# pwm register map
Vendor: Texas Instruments
Peripheral module from a debugger description file (folder sc4ce93xh6pm).
Registers are 32-bit, read-write, no defined reset value unless marked. A register's access mark holds for its fields unless they carry their own. Offsets are as the file gives them; lines under a group give offsets from that group; [hi:lo] are bit positions; {n}, {i} and the like mark numbered series; 'fields as' and 'values as' point back to an identical list; <NAME> marks a mode.

## PWM0 — PWM register offsets
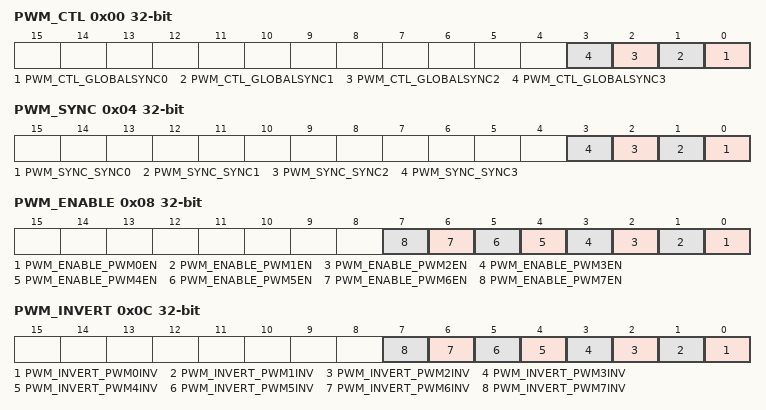
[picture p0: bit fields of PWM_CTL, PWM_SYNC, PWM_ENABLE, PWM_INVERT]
0x00 PWM_CTL — PWM Master Control
  [n] PWM_CTL_GLOBALSYNC{n} (n=0..3) — Update PWM Generator {n}
0x04 PWM_SYNC — PWM Time Base Sync
  [n] PWM_SYNC_SYNC{n} (n=0..3) — Reset Generator {n} Counter
0x08 PWM_ENABLE — PWM Output Enable
  [n] PWM_ENABLE_PWM{n}EN (n=0..7) — MnPWM{n} Output Enable
0x0C PWM_INVERT — PWM Output Inversion
  [n] PWM_INVERT_PWM{n}INV (n=0..7) — Invert MnPWM{n} Signal
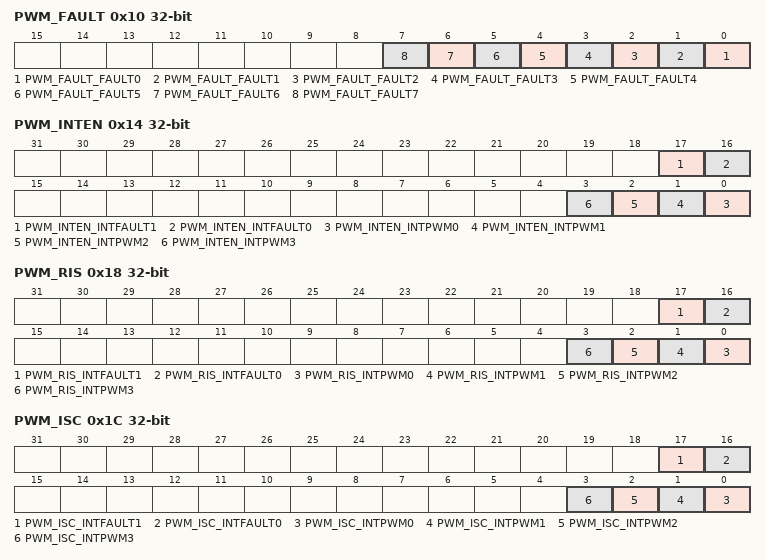
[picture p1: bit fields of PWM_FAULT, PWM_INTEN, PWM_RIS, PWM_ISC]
0x10 PWM_FAULT — PWM Output Fault
  [n] PWM_FAULT_FAULT{n} (n=0..7) — MnPWM{n} Fault
0x14 PWM_INTEN — PWM Interrupt Enable
  [17] PWM_INTEN_INTFAULT1 — Interrupt Fault 1
  [16] PWM_INTEN_INTFAULT0 — Interrupt Fault 0
  [n] PWM_INTEN_INTPWM{n} (n=0..3) — PWM{n} Interrupt Enable
0x18 PWM_RIS ro — PWM Raw Interrupt Status
  [17] PWM_RIS_INTFAULT1 — Interrupt Fault PWM 1
  [16] PWM_RIS_INTFAULT0 — Interrupt Fault PWM 0
  [n] PWM_RIS_INTPWM{n} (n=0..3) — PWM{n} Interrupt Asserted
0x1C PWM_ISC — PWM Interrupt Status and Clear
  [17] PWM_ISC_INTFAULT1 — FAULT1 Interrupt Asserted
  [16] PWM_ISC_INTFAULT0 — FAULT0 Interrupt Asserted
  [n] PWM_ISC_INTPWM{n} (n=0..3) — PWM{n} Interrupt Status
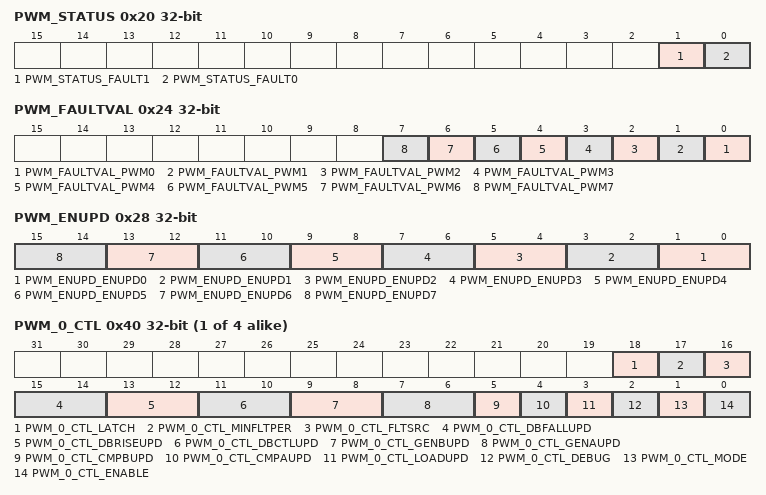
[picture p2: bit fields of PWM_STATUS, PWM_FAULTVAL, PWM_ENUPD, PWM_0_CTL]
0x20 PWM_STATUS ro
  [1] PWM_STATUS_FAULT1 — Generator 1 Fault Status
  [0] PWM_STATUS_FAULT0 — Generator 0 Fault Status
0x24 PWM_FAULTVAL — PWM Fault Condition Value
  [n] PWM_FAULTVAL_PWM{n} (n=0..7) — MnPWM{n} Fault Value
0x28 PWM_ENUPD — PWM Enable Update
  [2n+1:2n] PWM_ENUPD_ENUPD{n} (n=0..7) — MnPWM{n} Enable Update Mode
    0=PWM_ENUPD_ENUPD{n}_IMM (Immediate); 2=PWM_ENUPD_ENUPD{n}_LSYNC (Locally Synchronized); 3=PWM_ENUPD_ENUPD{n}_GSYNC (Globally Synchronized)
{0x40+0x40*i} PWM_{i}_CTL (i=0..3) — PWM{i} Control
  [18] PWM_{i}_CTL_LATCH — Latch Fault Input
  [17] PWM_{i}_CTL_MINFLTPER — Minimum Fault Period
  [16] PWM_{i}_CTL_FLTSRC — Fault Condition Source
  [15:14] PWM_{i}_CTL_DBFALLUPD — PWMnDBFALL Update Mode
    0=PWM_{i}_CTL_DBFALLUPD_I (Immediate); 2=PWM_{i}_CTL_DBFALLUPD_LS (Locally Synchronized); 3=PWM_{i}_CTL_DBFALLUPD_GS (Globally Synchronized)
  [13:12] PWM_{i}_CTL_DBRISEUPD — PWMnDBRISE Update Mode
    0=PWM_{i}_CTL_DBRISEUPD_I (Immediate); 2=PWM_{i}_CTL_DBRISEUPD_LS (Locally Synchronized); 3=PWM_{i}_CTL_DBRISEUPD_GS (Globally Synchronized)
  [11:10] PWM_{i}_CTL_DBCTLUPD — PWMnDBCTL Update Mode
    0=PWM_{i}_CTL_DBCTLUPD_I (Immediate); 2=PWM_{i}_CTL_DBCTLUPD_LS (Locally Synchronized); 3=PWM_{i}_CTL_DBCTLUPD_GS (Globally Synchronized)
  [9:8] PWM_{i}_CTL_GENBUPD — PWMnGENB Update Mode
    0=PWM_{i}_CTL_GENBUPD_I (Immediate); 2=PWM_{i}_CTL_GENBUPD_LS (Locally Synchronized); 3=PWM_{i}_CTL_GENBUPD_GS (Globally Synchronized)
  [7:6] PWM_{i}_CTL_GENAUPD — PWMnGENA Update Mode
    0=PWM_{i}_CTL_GENAUPD_I (Immediate); 2=PWM_{i}_CTL_GENAUPD_LS (Locally Synchronized); 3=PWM_{i}_CTL_GENAUPD_GS (Globally Synchronized)
  [5] PWM_{i}_CTL_CMPBUPD — Comparator B Update Mode
  [4] PWM_{i}_CTL_CMPAUPD — Comparator A Update Mode
  [3] PWM_{i}_CTL_LOADUPD — Load Register Update Mode
  [2] PWM_{i}_CTL_DEBUG — Debug Mode
  [1] PWM_{i}_CTL_MODE — Counter Mode
  [0] PWM_{i}_CTL_ENABLE — PWM Block Enable
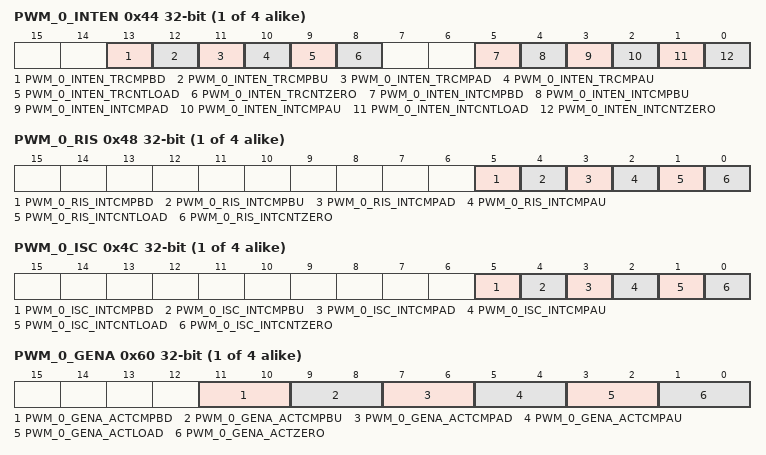
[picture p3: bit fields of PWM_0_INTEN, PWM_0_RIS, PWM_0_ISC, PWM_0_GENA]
{0x44+0x40*i} PWM_{i}_INTEN (i=0..3) — PWM{i} Interrupt and Trigger Enable
  [13] PWM_{i}_INTEN_TRCMPBD — Trigger for Counter=PWMnCMPB Down
  [12] PWM_{i}_INTEN_TRCMPBU — Trigger for Counter=PWMnCMPB Up
  [11] PWM_{i}_INTEN_TRCMPAD — Trigger for Counter=PWMnCMPA Down
  [10] PWM_{i}_INTEN_TRCMPAU — Trigger for Counter=PWMnCMPA Up
  [9] PWM_{i}_INTEN_TRCNTLOAD — Trigger for Counter=PWMnLOAD
  [8] PWM_{i}_INTEN_TRCNTZERO — Trigger for Counter=0
  [5] PWM_{i}_INTEN_INTCMPBD — Interrupt for Counter=PWMnCMPB Down
  [4] PWM_{i}_INTEN_INTCMPBU — Interrupt for Counter=PWMnCMPB Up
  [3] PWM_{i}_INTEN_INTCMPAD — Interrupt for Counter=PWMnCMPA Down
  [2] PWM_{i}_INTEN_INTCMPAU — Interrupt for Counter=PWMnCMPA Up
  [1] PWM_{i}_INTEN_INTCNTLOAD — Interrupt for Counter=PWMnLOAD
  [0] PWM_{i}_INTEN_INTCNTZERO — Interrupt for Counter=0
{0x48+0x40*i} PWM_{i}_RIS ro (i=0..3) — PWM{i} Raw Interrupt Status
  [5] PWM_{i}_RIS_INTCMPBD — Comparator B Down Interrupt Status
  [4] PWM_{i}_RIS_INTCMPBU — Comparator B Up Interrupt Status
  [3] PWM_{i}_RIS_INTCMPAD — Comparator A Down Interrupt Status
  [2] PWM_{i}_RIS_INTCMPAU — Comparator A Up Interrupt Status
  [1] PWM_{i}_RIS_INTCNTLOAD — Counter=Load Interrupt Status
  [0] PWM_{i}_RIS_INTCNTZERO — Counter=0 Interrupt Status
{0x4C+0x40*i} PWM_{i}_ISC (i=0..3) — PWM{i} Interrupt Status and Clear
  [5] PWM_{i}_ISC_INTCMPBD — Comparator B Down Interrupt
  [4] PWM_{i}_ISC_INTCMPBU — Comparator B Up Interrupt
  [3] PWM_{i}_ISC_INTCMPAD — Comparator A Down Interrupt
  [2] PWM_{i}_ISC_INTCMPAU — Comparator A Up Interrupt
  [1] PWM_{i}_ISC_INTCNTLOAD — Counter=Load Interrupt
  [0] PWM_{i}_ISC_INTCNTZERO — Counter=0 Interrupt
0x50 PWM_0_LOAD
  [15:0] PWM_0_LOAD — Counter Load Value
0x54 PWM_0_COUNT ro — PWM0 Counter
  [15:0] PWM_0_COUNT — Counter Value
0x58 PWM_0_CMPA — PWM0 Compare A
  [15:0] PWM_0_CMPA — Comparator A Value
0x5C PWM_0_CMPB — PWM0 Compare B
  [15:0] PWM_0_CMPB — Comparator B Value
{0x60+0x40*i} PWM_{i}_GENA (i=0..3) — PWM{i} Generator A Control
  [11:10] PWM_{i}_GENA_ACTCMPBD — Action for Comparator B Down
    0=PWM_{i}_GENA_ACTCMPBD_NONE (Do nothing); 1=PWM_{i}_GENA_ACTCMPBD_INV (Invert pwmA); 2=PWM_{i}_GENA_ACTCMPBD_ZERO (Drive pwmA Low); 3=PWM_{i}_GENA_ACTCMPBD_ONE (Drive pwmA High)
  [9:8] PWM_{i}_GENA_ACTCMPBU — Action for Comparator B Up
    0=PWM_{i}_GENA_ACTCMPBU_NONE (Do nothing); 1=PWM_{i}_GENA_ACTCMPBU_INV (Invert pwmA); 2=PWM_{i}_GENA_ACTCMPBU_ZERO (Drive pwmA Low); 3=PWM_{i}_GENA_ACTCMPBU_ONE (Drive pwmA High)
  [7:6] PWM_{i}_GENA_ACTCMPAD — Action for Comparator A Down
    0=PWM_{i}_GENA_ACTCMPAD_NONE (Do nothing); 1=PWM_{i}_GENA_ACTCMPAD_INV (Invert pwmA); 2=PWM_{i}_GENA_ACTCMPAD_ZERO (Drive pwmA Low); 3=PWM_{i}_GENA_ACTCMPAD_ONE (Drive pwmA High)
  [5:4] PWM_{i}_GENA_ACTCMPAU — Action for Comparator A Up
    0=PWM_{i}_GENA_ACTCMPAU_NONE (Do nothing); 1=PWM_{i}_GENA_ACTCMPAU_INV (Invert pwmA); 2=PWM_{i}_GENA_ACTCMPAU_ZERO (Drive pwmA Low); 3=PWM_{i}_GENA_ACTCMPAU_ONE (Drive pwmA High)
  [3:2] PWM_{i}_GENA_ACTLOAD — Action for Counter=LOAD
    0=PWM_{i}_GENA_ACTLOAD_NONE (Do nothing); 1=PWM_{i}_GENA_ACTLOAD_INV (Invert pwmA); 2=PWM_{i}_GENA_ACTLOAD_ZERO (Drive pwmA Low); 3=PWM_{i}_GENA_ACTLOAD_ONE (Drive pwmA High)
  [1:0] PWM_{i}_GENA_ACTZERO — Action for Counter=0
    0=PWM_{i}_GENA_ACTZERO_NONE (Do nothing); 1=PWM_{i}_GENA_ACTZERO_INV (Invert pwmA); 2=PWM_{i}_GENA_ACTZERO_ZERO (Drive pwmA Low); 3=PWM_{i}_GENA_ACTZERO_ONE (Drive pwmA High)
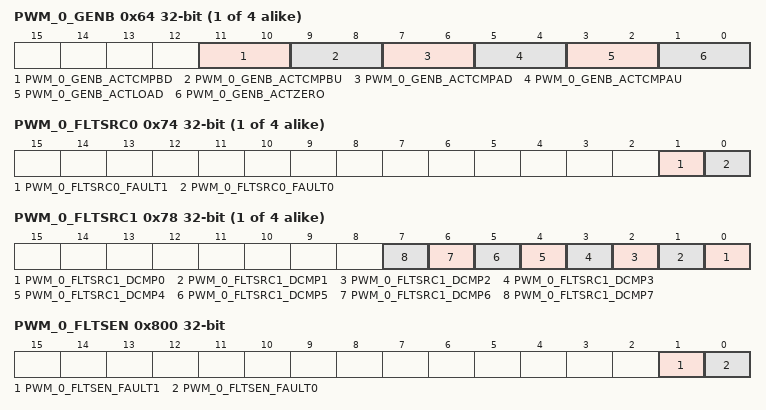
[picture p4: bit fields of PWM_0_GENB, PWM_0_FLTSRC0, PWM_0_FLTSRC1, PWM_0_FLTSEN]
{0x64+0x40*i} PWM_{i}_GENB (i=0..3) — PWM{i} Generator B Control
  [11:10] PWM_{i}_GENB_ACTCMPBD — Action for Comparator B Down
    0=PWM_{i}_GENB_ACTCMPBD_NONE (Do nothing); 1=PWM_{i}_GENB_ACTCMPBD_INV (Invert pwmB); 2=PWM_{i}_GENB_ACTCMPBD_ZERO (Drive pwmB Low); 3=PWM_{i}_GENB_ACTCMPBD_ONE (Drive pwmB High)
  [9:8] PWM_{i}_GENB_ACTCMPBU — Action for Comparator B Up
    0=PWM_{i}_GENB_ACTCMPBU_NONE (Do nothing); 1=PWM_{i}_GENB_ACTCMPBU_INV (Invert pwmB); 2=PWM_{i}_GENB_ACTCMPBU_ZERO (Drive pwmB Low); 3=PWM_{i}_GENB_ACTCMPBU_ONE (Drive pwmB High)
  [7:6] PWM_{i}_GENB_ACTCMPAD — Action for Comparator A Down
    0=PWM_{i}_GENB_ACTCMPAD_NONE (Do nothing); 1=PWM_{i}_GENB_ACTCMPAD_INV (Invert pwmB); 2=PWM_{i}_GENB_ACTCMPAD_ZERO (Drive pwmB Low); 3=PWM_{i}_GENB_ACTCMPAD_ONE (Drive pwmB High)
  [5:4] PWM_{i}_GENB_ACTCMPAU — Action for Comparator A Up
    0=PWM_{i}_GENB_ACTCMPAU_NONE (Do nothing); 1=PWM_{i}_GENB_ACTCMPAU_INV (Invert pwmB); 2=PWM_{i}_GENB_ACTCMPAU_ZERO (Drive pwmB Low); 3=PWM_{i}_GENB_ACTCMPAU_ONE (Drive pwmB High)
  [3:2] PWM_{i}_GENB_ACTLOAD — Action for Counter=LOAD
    0=PWM_{i}_GENB_ACTLOAD_NONE (Do nothing); 1=PWM_{i}_GENB_ACTLOAD_INV (Invert pwmB); 2=PWM_{i}_GENB_ACTLOAD_ZERO (Drive pwmB Low); 3=PWM_{i}_GENB_ACTLOAD_ONE (Drive pwmB High)
  [1:0] PWM_{i}_GENB_ACTZERO — Action for Counter=0
    0=PWM_{i}_GENB_ACTZERO_NONE (Do nothing); 1=PWM_{i}_GENB_ACTZERO_INV (Invert pwmB); 2=PWM_{i}_GENB_ACTZERO_ZERO (Drive pwmB Low); 3=PWM_{i}_GENB_ACTZERO_ONE (Drive pwmB High)
{0x68+0x40*i} PWM_{i}_DBCTL (i=0..3) — PWM{i} Dead-Band Control
  [0] PWM_{i}_DBCTL_ENABLE — Dead-Band Generator Enable
0x6C PWM_0_DBRISE — PWM0 Dead-Band Rising-Edge Delay
  [11:0] PWM_0_DBRISE_DELAY — Dead-Band Rise Delay
0x70 PWM_0_DBFALL — PWM0 Dead-Band Falling-Edge-Delay
  [11:0] PWM_0_DBFALL_DELAY — Dead-Band Fall Delay
{0x74+0x40*i} PWM_{i}_FLTSRC0 (i=0..3) — PWM{i} Fault Source 0
  [1] PWM_{i}_FLTSRC0_FAULT1 — Fault1 Input
  [0] PWM_{i}_FLTSRC0_FAULT0 — Fault0 Input
{0x78+0x40*i} PWM_{i}_FLTSRC1 (i=0..3) — PWM{i} Fault Source 1
  [n] PWM_{i}_FLTSRC1_DCMP{n} (n=0..7) — Digital Comparator {n}
0x7C PWM_0_MINFLTPER — PWM0 Minimum Fault Period
  [15:0] PWM_0_MINFLTPER — Minimum Fault Period
{0x50+0x40*i} PWM_{i}_LOAD (i=1..3)
  [15:0] PWM_{i}_LOAD_LOAD — Counter Load Value
{0x54+0x40*i} PWM_{i}_COUNT ro (i=1..3) — PWM{i} Counter
  [15:0] PWM_{i}_COUNT_COUNT — Counter Value
{0x58+0x40*i} PWM_{i}_CMPA (i=1..3) — PWM{i} Compare A
  [15:0] PWM_{i}_CMPA_COMPA — Comparator A Value
{0x5C+0x40*i} PWM_{i}_CMPB (i=1..3) — PWM{i} Compare B
  [15:0] PWM_{i}_CMPB_COMPB — Comparator B Value
{0x6C+0x40*i} PWM_{i}_DBRISE (i=1..3) — PWM{i} Dead-Band Rising-Edge Delay
  [11:0] PWM_{i}_DBRISE_RISEDELAY — Dead-Band Rise Delay
{0x70+0x40*i} PWM_{i}_DBFALL (i=1..3) — PWM{i} Dead-Band Falling-Edge-Delay
  [11:0] PWM_{i}_DBFALL_FALLDELAY — Dead-Band Fall Delay
{0x7C+0x40*i} PWM_{i}_MINFLTPER (i=1..3) — PWM{i} Minimum Fault Period
  [15:0] PWM_{i}_MINFLTPER_MFP — Minimum Fault Period
0x800 PWM_0_FLTSEN — PWM0 Fault Pin Logic Sense
  [1] PWM_0_FLTSEN_FAULT1 — Fault1 Sense
  [0] PWM_0_FLTSEN_FAULT0 — Fault0 Sense
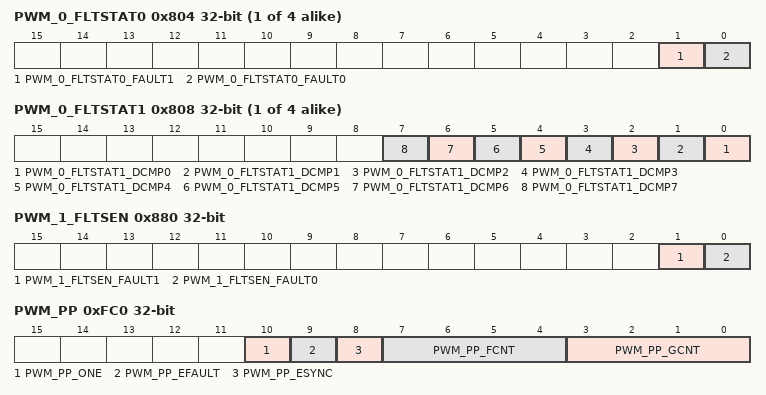
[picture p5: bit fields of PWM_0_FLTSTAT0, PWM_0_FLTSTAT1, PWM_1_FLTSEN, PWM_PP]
{0x804+0x80*i} PWM_{i}_FLTSTAT0 access not given (i=0..3) — PWM{i} Fault Status 0
  [1] PWM_{i}_FLTSTAT0_FAULT1 — Fault Input 1 (access N)
  [0] PWM_{i}_FLTSTAT0_FAULT0 — Fault Input 0 (access N)
{0x808+0x80*i} PWM_{i}_FLTSTAT1 access not given (i=0..3) — PWM{i} Fault Status 1
  [n] PWM_{i}_FLTSTAT1_DCMP{n} (n=0..7) — Digital Comparator {n} Trigger (access N)
0x880 PWM_1_FLTSEN — PWM1 Fault Pin Logic Sense
  [1] PWM_1_FLTSEN_FAULT1 — Fault1 Sense
  [0] PWM_1_FLTSEN_FAULT0 — Fault0 Sense
0xFC0 PWM_PP ro — PWM Peripheral Properties
  [10] PWM_PP_ONE — One-Shot Mode
  [9] PWM_PP_EFAULT — Extended Fault
  [8] PWM_PP_ESYNC — Extended Synchronization
  [7:4] PWM_PP_FCNT — Fault Inputs (per PWM unit)
  [3:0] PWM_PP_GCNT — Generators
